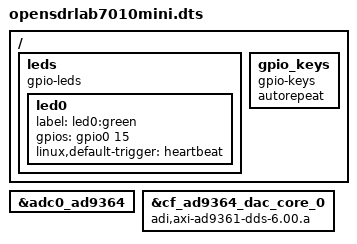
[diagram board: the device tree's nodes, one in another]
// SPDX-License-Identifier: GPL-2.0
/*
 * OpenSDRLab 7010 Mini (Z7010/AD9363)
 *
 * hdl_project: <opensdrlab7010mini>
 * board_revision: <A>
 */
/dts-v1/;
#include "opensdrlab7010mini.dtsi"


&adc0_ad9364 {
	// This property is controlled by u-boot environment.
	// opensdrlab7010mini has only one RX/TX chain.
	//adi,2rx-2tx-mode-enable;
};

&cf_ad9364_dac_core_0 {
	/* This property is controlled by u-boot environment. */
	compatible = "adi,axi-ad9361-dds-6.00.a";
};

/ {
	leds {
		compatible = "gpio-leds";
		led0 {
			label = "led0:green";
			gpios = <&gpio0 15 0>;
			linux,default-trigger = "heartbeat";
		};
	};

	gpio_keys {
		compatible = "gpio-keys";
		#address-cells = <1>;
		#size-cells = <0>;
		autorepeat;
	};


};
